# liliumSOC1_sysctrl register map
Vendor: Nordic Semiconductor; Series: liliumSOC1; File version: 1
Registers are 32-bit, read-write, reset 0x0 unless marked. A register's access mark holds for its fields unless they carry their own. Offsets are from the block's base; [hi:lo] are bit positions; lines under a group give offsets from that group; {n}, {i} and the like mark numbered series; 'fields as' and 'values as' point back to an identical list.

## GLOBAL_STMDATA_NS — System Trace Macrocell data buffer 0
Base 0xA0000000
Same registers: GLOBAL_STMDATA_S 0xA0000000 (alternate view of GLOBAL_STMDATA_NS)
{0x0+0x2000000*i} DOMAIN[{i}] (i=0..15) group — Unspecified
  {0x0+j} NSDATA[{j}] (j=0..16777215) 8-bit — Description collection: NonSecure STM output data buffer for domain n. Writes to this region generates trace packets with id n+96.
  {0x1000000+j} SDATA[{j}] (j=0..16777215) 8-bit — Description collection: Secure STM output data buffer for domain n. Writes to this region generates trace packets with id n+32.
{0x0+0x1000000*i} BUFFER[{i}] (i=0..15) group (alternate view of DOMAIN[{i}]) — Raw buffer access to STM array. Use when DOMAIN array does not apply.
  {0x0+j} DATA[{j}] (j=0..16777215) 8-bit — Description collection: STM output data buffer n. Writes to this region generates trace packets.

## GLOBAL_TDDCONF_NS — TDDCONF 0
Base 0xBF001000
Same registers: GLOBAL_TDDCONF_S 0xBF001000 (alternate view of GLOBAL_TDDCONF_NS)
0x400 SYSPWRUPREQ — System power-up request
  [0] ACTIVE — Activate power-up request
    0=NotActive (Power-up request not active); 1=Active (Power-up request active)
0x404 DBGPWRUPREQ — Debug power-up request
  fields as SYSPWRUPREQ
0x408 TRACEPORTSPEED — Trace port trace clock speed
  [1:0] SPEED — Trace clock speed
    0=Speed25MHz; 1=Speed12500KHz (Speed 12.5MHz); 2=Speed6250KHz (Speed 6.25MHz); 3=Speed3125KHz (Speed 3.125MHz)
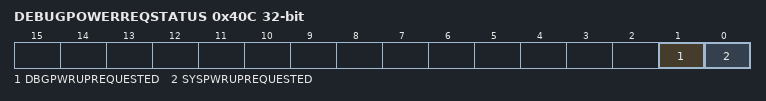
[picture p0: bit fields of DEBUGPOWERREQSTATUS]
0x40C DEBUGPOWERREQSTATUS ro — Combined effective system status of both SWJ-DP and TDDCONF registers originated power requests
  [1] DBGPWRUPREQUESTED — Debug domain powerup request status
    0=NoPowerReq (Power not requested); 1=Power requested
  [0] SYSPWRUPREQUESTED — System powerup request status
    0=NoPowerReq (Power not requested); 1=Power requested

## LRCCONF200_S — LRCCONF 0
Base 0xBF005000
Same registers: LRCCONF120_S 0x5F8CE000, LRCCONF130_S 0x5F93E000
{0x0+4i} TASKS_REQCLKSRC[{i}] (i=0..7) wo — Description collection: Request the clock source for clock [n]
  [0] TASKS_REQCLKSRC — Request the clock source for clock [n]
    1=Trigger task
{0x20+4i} TASKS_STOPREQCLKSRC[{i}] (i=0..7) wo — Description collection: Stop requesting the clock source for clock [n]
  [0] TASKS_STOPREQCLKSRC — Stop requesting the clock source for clock [n]
    1=Trigger task
0x40 TASKS_CONSTLAT group — Peripheral tasks.
  0x00 ENABLE wo — Enable constant latency mode
    [0] ENABLE
      1=Trigger task
  0x04 DISABLE wo — Disable constant latency mode
    [0] DISABLE
      1=Trigger task
0x48 TASKS_SYSTEMOFF group — Peripheral tasks.
  0x00 NOTREADY wo — Not ready to go to System OFF
    [0] NOTREADY
      1=Trigger task
  0x04 READY wo — Ready to go to System OFF
    [0] READY
      1=Trigger task
{0x100+4i} EVENTS_CLKSRCSTARTED[{i}] (i=0..7) — Description collection: Clock source is started for clock [n]
  [0] EVENTS_CLKSRCSTARTED — Clock source is started for clock [n]
    0=NotGenerated (Event not generated); 1=Generated (Event generated)
{0x400+8i} CLKSTAT[{i}] (i=0..7) group — Unspecified
  0x00 RUN — Description cluster: Status indicating that TASKS_REQCLKSRC task has been triggered for clock [n].
    [0] STATUS ro — Clock start task triggered or not
      0=NotTriggered (Task not triggered); 1=Triggered (Task triggered)
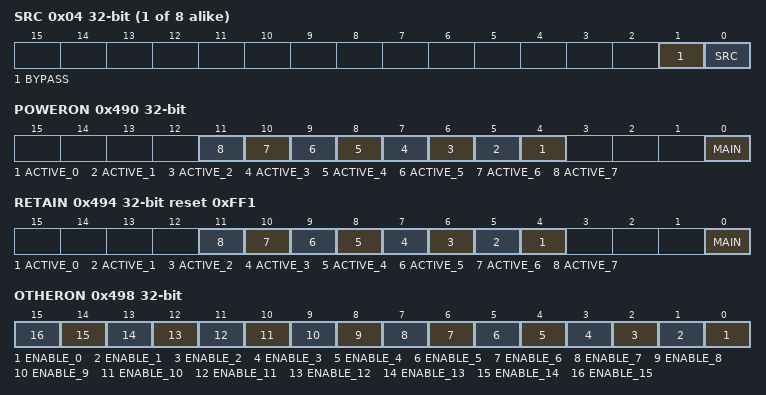
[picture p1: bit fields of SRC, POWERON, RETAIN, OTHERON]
  0x04 SRC — Description cluster: Status indicating clock source for clock [n]
    [1] BYPASS ro — Clock source bypass status
      0=Disable (Clock source bypass is disabled.); 1=Enable (Clock source bypass is enabled.)
    [0] SRC ro — Clock source status
      0=OpenLoop; 1=ClosedLoop
{0x440+8i} CLKCTRL[{i}] (i=0..7) group — Unspecified
  0x00 ALWAYSRUN — Description cluster: Force the clock [n] and tree running always
    [0] FORCE — Force the clock always running
      0=Automatic clock control enabled; 1=AlwaysRun (Clock always running)
  0x04 SRC — Description cluster: Select the clock source for clock [n]
    [1] BYPASS — Clock source bypass
      0=Disable the clock source bypass; 1=Enable the clock source bypass
    [0] SRC — Clock source
      0=OpenLoop; 1=ClosedLoop
0x480 CONSTLATSTAT ro — Status of constant latency
  [0] STATUS
    0=Disable (Constant latency disabled.); 1=Enable (Constant latency enabled.)
0x490 POWERON — Force power domain ON
  [all] fields
    0=Automatic power control enabled; 1=AlwaysOn (Keep the power domain ON even though there is no request)
  [n+4] ACTIVE_{n} (n=0..7) — Force the active power domain[{n}] ON
  [0] MAIN — Force the main power domain ON
0x494 RETAIN reset 0xFF1 — Retain power domain
  [all] fields
    0=Disable (Retain disabled); 1=Enable (Retain enabled)
  [n+4] ACTIVE_{n} (n=0..7) — Retain the active power domain[{n}]
  [0] MAIN ro — Retain the main power domain
0x498 OTHERON — Request other domain ON
  [all] fields
    0=Automatic power control enabled; 1=AlwaysOn (Request to keep the other power domain ON even though there is no request)
  [n] ENABLE_{n} (n=0..15) — Request power domain[{n}] ON
{0x500+4i} AX2XWAITSTATES[{i}] (i=0..15) reset 0x7 — Description collection: AX2X bridge waitstates for the domain [n], where n is the Domain ID.
  [2:0] WAITSTATES — Number of waitstates
